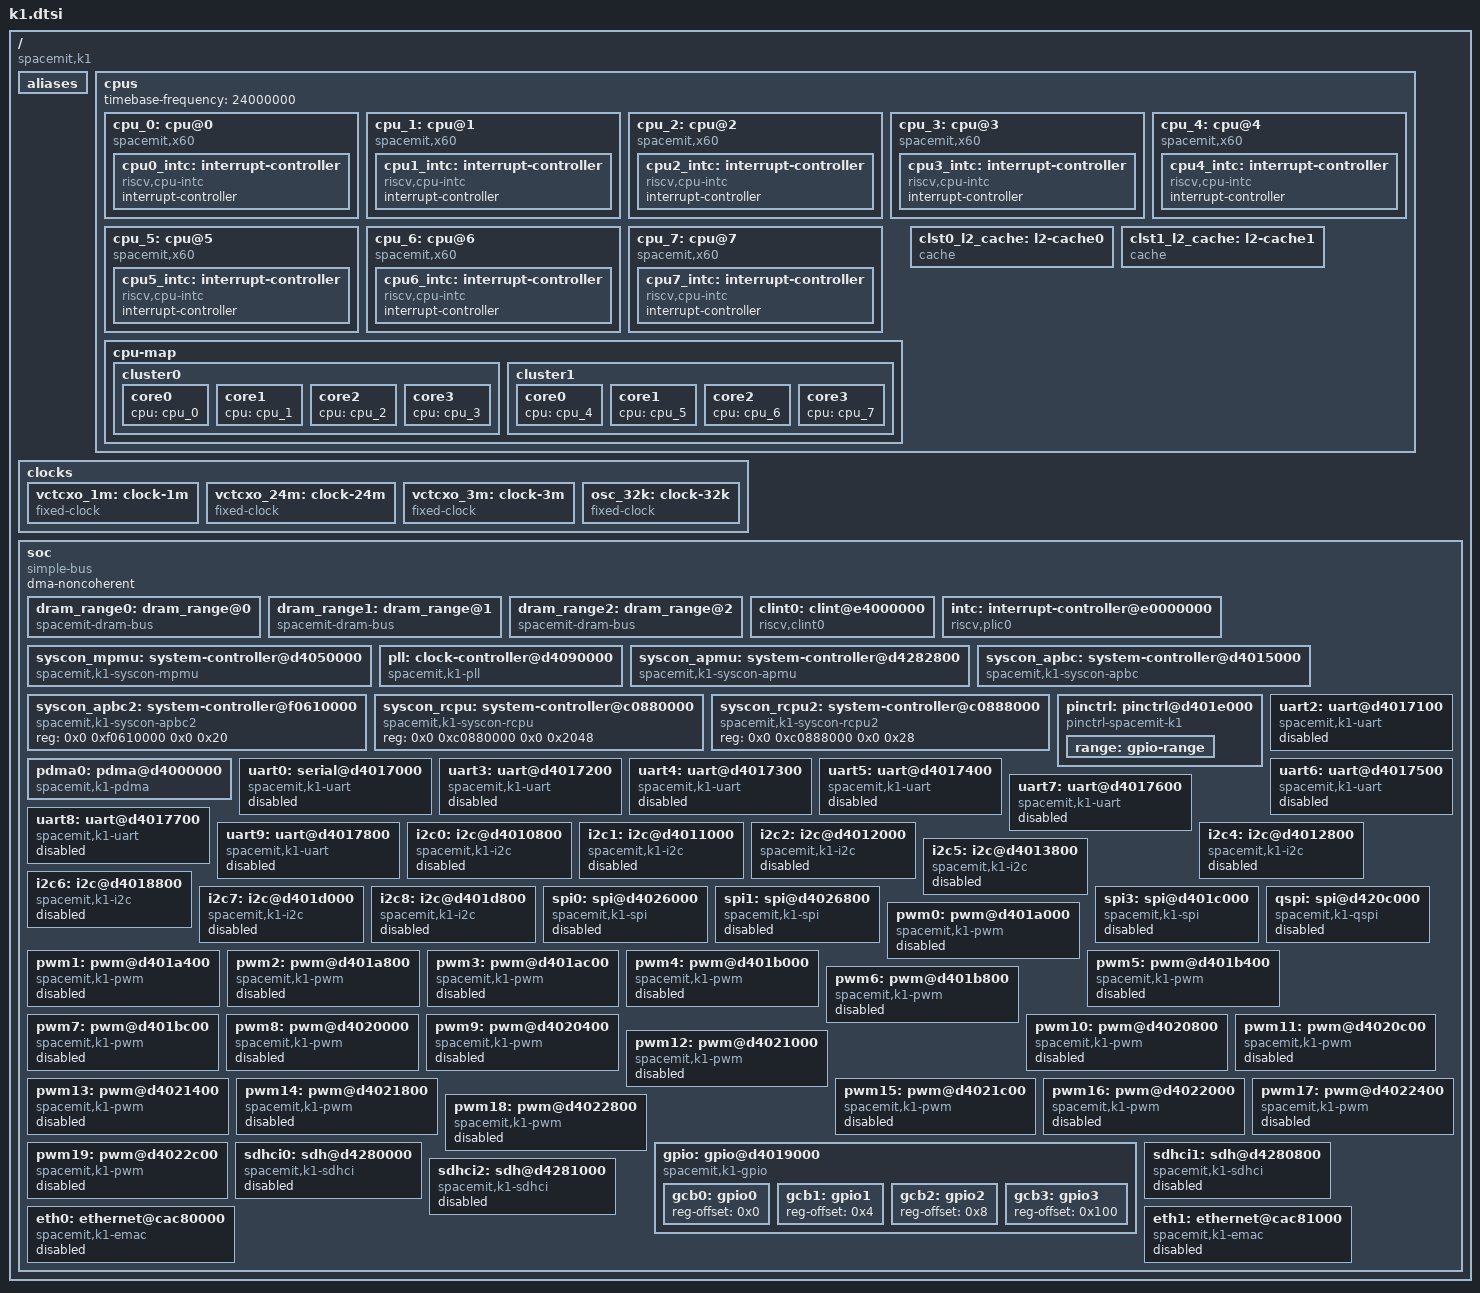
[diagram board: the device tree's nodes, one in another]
// SPDX-License-Identifier: (GPL-2.0 OR MIT)
/* Copyright (c) 2022 Spacemit, Inc */

/dts-v1/;

#include <dt-bindings/clock/spacemit,k1-syscon.h>
#include <dt-bindings/dma/spacemit-k1-dma.h>
#include <dt-bindings/mmc/spacemit-k1-sdhci.h>

/ {
	compatible = "spacemit,k1";
	#address-cells = <2>;
	#size-cells = <2>;

	aliases {
		serial0 = &uart0;
		serial1 = &uart2;
		serial2 = &uart3;
		serial3 = &uart4;
		serial4 = &uart5;
		serial5 = &uart6;
		serial6 = &uart7;
		serial7 = &uart8;
		serial8 = &uart9;
		mmc0 = &sdhci0;
		mmc1 = &sdhci1;
		mmc2 = &sdhci2;
		ethernet0 = &eth0;
		ethernet1 = &eth1;
	};

	cpus: cpus {
		#address-cells = <1>;
		#size-cells = <0>;
		timebase-frequency = <24000000>;
		cpu_0: cpu@0 {
			compatible = "spacemit,x60", "riscv";
			device_type = "cpu";
			model = "Spacemit(R) X60";
			reg = <0>;
			status = "okay";
			riscv,isa = "rv64imafdcv";
			riscv,isa-base = "rv64i";
			riscv,isa-extensions = "i", "m", "a", "f", "d", "c", "v",
					"zicbom", "zicboz", "zicntr", "zicond",
					"zicsr", "zifencei", "zihintpause", "zihpm",
					"zfh", "zfhmin", "zba", "zbb", "zbc", "zbs",
					"zkt", "zvfh", "zvfhmin", "zvkt", "sscofpmf",
					"sstc", "svinval", "svnapot", "svpbmt" ;
			riscv,cbom-block-size = <64>;
			riscv,cboz-block-size = <64>;
			i-cache-block-size = <64>;
			i-cache-size = <32768>;
			i-cache-sets = <128>;
			d-cache-block-size = <64>;
			d-cache-size = <32768>;
			d-cache-sets = <128>;
			next-level-cache = <&clst0_l2_cache>;
			mmu-type = "riscv,sv39";
			cpu-ai = "true";

			cpu0_intc: interrupt-controller {
				#interrupt-cells = <1>;
				compatible = "riscv,cpu-intc";
				interrupt-controller;
			};
		};

		cpu_1: cpu@1 {
			device_type = "cpu";
			reg = <1>;
			status = "okay";
			compatible = "spacemit,x60", "riscv";
			model = "Spacemit(R) X60";
			riscv,isa = "rv64imafdcv";
			riscv,isa-base = "rv64i";
			riscv,isa-extensions = "i", "m", "a", "f", "d", "c", "v",
					"zicbom", "zicboz", "zicntr", "zicond",
					"zicsr", "zifencei", "zihintpause", "zihpm",
					"zfh", "zfhmin", "zba", "zbb", "zbc", "zbs",
					"zkt", "zvfh", "zvfhmin", "zvkt", "sscofpmf",
					"sstc", "svinval", "svnapot", "svpbmt" ;
			riscv,cbom-block-size = <64>;
			riscv,cboz-block-size = <64>;
			i-cache-block-size = <64>;
			i-cache-size = <32768>;
			i-cache-sets = <128>;
			d-cache-block-size = <64>;
			d-cache-size = <32768>;
			d-cache-sets = <128>;
			next-level-cache = <&clst0_l2_cache>;
			mmu-type = "riscv,sv39";
			cpu-ai = "true";

			cpu1_intc: interrupt-controller {
				#interrupt-cells = <1>;
				compatible = "riscv,cpu-intc";
				interrupt-controller;
			};
		};

		cpu_2: cpu@2 {
			device_type = "cpu";
			reg = <2>;
			status = "okay";
			compatible = "spacemit,x60", "riscv";
			model = "Spacemit(R) X60";
			riscv,isa = "rv64imafdcv";
			riscv,isa-base = "rv64i";
			riscv,isa-extensions = "i", "m", "a", "f", "d", "c", "v",
					"zicbom", "zicboz", "zicntr", "zicond",
					"zicsr", "zifencei", "zihintpause", "zihpm",
					"zfh", "zfhmin", "zba", "zbb", "zbc", "zbs",
					"zkt", "zvfh", "zvfhmin", "zvkt", "sscofpmf",
					"sstc", "svinval", "svnapot", "svpbmt" ;
			riscv,cbom-block-size = <64>;
			riscv,cboz-block-size = <64>;
			i-cache-block-size = <64>;
			i-cache-size = <32768>;
			i-cache-sets = <128>;
			d-cache-block-size = <64>;
			d-cache-size = <32768>;
			d-cache-sets = <128>;
			next-level-cache = <&clst0_l2_cache>;
			mmu-type = "riscv,sv39";
			cpu-ai = "true";

			cpu2_intc: interrupt-controller {
				#interrupt-cells = <1>;
				compatible = "riscv,cpu-intc";
				interrupt-controller;
			};
		};

		cpu_3: cpu@3 {
			device_type = "cpu";
			reg = <3>;
			status = "okay";
			compatible = "spacemit,x60", "riscv";
			model = "Spacemit(R) X60";
			riscv,isa = "rv64imafdcv";
			riscv,isa-base = "rv64i";
			riscv,isa-extensions = "i", "m", "a", "f", "d", "c", "v",
					"zicbom", "zicboz", "zicntr", "zicond",
					"zicsr", "zifencei", "zihintpause", "zihpm",
					"zfh", "zfhmin", "zba", "zbb", "zbc", "zbs",
					"zkt", "zvfh", "zvfhmin", "zvkt", "sscofpmf",
					"sstc", "svinval", "svnapot", "svpbmt" ;
			riscv,cbom-block-size = <64>;
			riscv,cboz-block-size = <64>;
			i-cache-block-size = <64>;
			i-cache-size = <32768>;
			i-cache-sets = <128>;
			d-cache-block-size = <64>;
			d-cache-size = <32768>;
			d-cache-sets = <128>;
			next-level-cache = <&clst0_l2_cache>;
			mmu-type = "riscv,sv39";
			cpu-ai = "true";

			cpu3_intc: interrupt-controller {
				#interrupt-cells = <1>;
				compatible = "riscv,cpu-intc";
				interrupt-controller;
			};
		};

		cpu_4: cpu@4 {
			device_type = "cpu";
			reg = <4>;
			status = "okay";
			compatible = "spacemit,x60", "riscv";
			model = "Spacemit(R) X60";
			riscv,isa = "rv64imafdcv";
			riscv,isa-base = "rv64i";
			riscv,isa-extensions = "i", "m", "a", "f", "d", "c", "v",
					"zicbom", "zicboz", "zicntr", "zicond",
					"zicsr", "zifencei", "zihintpause", "zihpm",
					"zfh", "zfhmin", "zba", "zbb", "zbc", "zbs",
					"zkt", "zvfh", "zvfhmin", "zvkt", "sscofpmf",
					"sstc", "svinval", "svnapot", "svpbmt" ;
			riscv,cbom-block-size = <64>;
			riscv,cboz-block-size = <64>;
			i-cache-block-size = <64>;
			i-cache-size = <32768>;
			i-cache-sets = <128>;
			d-cache-block-size = <64>;
			d-cache-size = <32768>;
			d-cache-sets = <128>;
			next-level-cache = <&clst1_l2_cache>;
			mmu-type = "riscv,sv39";

			cpu4_intc: interrupt-controller {
				#interrupt-cells = <1>;
				compatible = "riscv,cpu-intc";
				interrupt-controller;
			};
		};

		cpu_5: cpu@5 {
			device_type = "cpu";
			reg = <5>;
			status = "okay";
			compatible = "spacemit,x60", "riscv";
			model = "Spacemit(R) X60";
			riscv,isa = "rv64imafdcv";
			riscv,isa-base = "rv64i";
			riscv,isa-extensions = "i", "m", "a", "f", "d", "c", "v",
					"zicbom", "zicboz", "zicntr", "zicond",
					"zicsr", "zifencei", "zihintpause", "zihpm",
					"zfh", "zfhmin", "zba", "zbb", "zbc", "zbs",
					"zkt", "zvfh", "zvfhmin", "zvkt", "sscofpmf",
					"sstc", "svinval", "svnapot", "svpbmt" ;
			riscv,cbom-block-size = <64>;
			riscv,cboz-block-size = <64>;
			i-cache-block-size = <64>;
			i-cache-size = <32768>;
			i-cache-sets = <128>;
			d-cache-block-size = <64>;
			d-cache-size = <32768>;
			d-cache-sets = <128>;
			next-level-cache = <&clst1_l2_cache>;
			mmu-type = "riscv,sv39";

			cpu5_intc: interrupt-controller {
				#interrupt-cells = <1>;
				compatible = "riscv,cpu-intc";
				interrupt-controller;
			};
		};

		cpu_6: cpu@6 {
			device_type = "cpu";
			reg = <6>;
			status = "okay";
			compatible = "spacemit,x60", "riscv";
			model = "Spacemit(R) X60";
			riscv,isa = "rv64imafdcv";
			riscv,isa-base = "rv64i";
			riscv,isa-extensions = "i", "m", "a", "f", "d", "c", "v",
					"zicbom", "zicboz", "zicntr", "zicond",
					"zicsr", "zifencei", "zihintpause", "zihpm",
					"zfh", "zfhmin", "zba", "zbb", "zbc", "zbs",
					"zkt", "zvfh", "zvfhmin", "zvkt", "sscofpmf",
					"sstc", "svinval", "svnapot", "svpbmt" ;
			riscv,cbom-block-size = <64>;
			riscv,cboz-block-size = <64>;
			i-cache-block-size = <64>;
			i-cache-size = <32768>;
			i-cache-sets = <128>;
			d-cache-block-size = <64>;
			d-cache-size = <32768>;
			d-cache-sets = <128>;
			next-level-cache = <&clst1_l2_cache>;
			mmu-type = "riscv,sv39";

			cpu6_intc: interrupt-controller {
				#interrupt-cells = <1>;
				compatible = "riscv,cpu-intc";
				interrupt-controller;
			};
		};

		cpu_7: cpu@7 {
			device_type = "cpu";
			reg = <7>;
			status = "okay";
			compatible = "spacemit,x60", "riscv";
			model = "Spacemit(R) X60";
			riscv,isa = "rv64imafdcv";
			riscv,isa-base = "rv64i";
			riscv,isa-extensions = "i", "m", "a", "f", "d", "c", "v",
					"zicbom", "zicboz", "zicntr", "zicond",
					"zicsr", "zifencei", "zihintpause", "zihpm",
					"zfh", "zfhmin", "zba", "zbb", "zbc", "zbs",
					"zkt", "zvfh", "zvfhmin", "zvkt", "sscofpmf",
					"sstc", "svinval", "svnapot", "svpbmt" ;
			riscv,cbom-block-size = <64>;
			riscv,cboz-block-size = <64>;
			i-cache-block-size = <64>;
			i-cache-size = <32768>;
			i-cache-sets = <128>;
			d-cache-block-size = <64>;
			d-cache-size = <32768>;
			d-cache-sets = <128>;
			next-level-cache = <&clst1_l2_cache>;
			mmu-type = "riscv,sv39";

			cpu7_intc: interrupt-controller {
				#interrupt-cells = <1>;
				compatible = "riscv,cpu-intc";
				interrupt-controller;
			};
		};

		cpu-map {
			cluster0 {
				core0 {
					cpu = <&cpu_0>;
				};

				core1 {
					cpu = <&cpu_1>;
				};

				core2 {
					cpu = <&cpu_2>;
				};

				core3 {
					cpu = <&cpu_3>;
				};
			};

			cluster1 {
				core0 {
					cpu = <&cpu_4>;
				};

				core1 {
					cpu = <&cpu_5>;
				};

				core2 {
					cpu = <&cpu_6>;
				};

				core3 {
					cpu = <&cpu_7>;
				};
			};
		};

		clst0_l2_cache: l2-cache0 {
			compatible = "cache";
			cache-block-size = <64>;
			cache-level = <2>;
			cache-size = <524288>;
			cache-sets = <512>;
			cache-unified;
		};

		clst1_l2_cache: l2-cache1 {
			compatible = "cache";
			cache-block-size = <64>;
			cache-level = <2>;
			cache-size = <524288>;
			cache-sets = <512>;
			cache-unified;
		};
	};

	clocks {
		vctcxo_1m: clock-1m {
			compatible = "fixed-clock";
			clock-frequency = <1000000>;
			clock-output-names = "vctcxo_1m";
			#clock-cells = <0>;
		};

		vctcxo_24m: clock-24m {
			compatible = "fixed-clock";
			clock-frequency = <24000000>;
			clock-output-names = "vctcxo_24m";
			#clock-cells = <0>;
		};

		vctcxo_3m: clock-3m {
			compatible = "fixed-clock";
			clock-frequency = <3000000>;
			clock-output-names = "vctcxo_3m";
			#clock-cells = <0>;
		};

		osc_32k: clock-32k {
			compatible = "fixed-clock";
			clock-frequency = <32000>;
			clock-output-names = "osc_32k";
			#clock-cells = <0>;
		};
	};

	soc: soc {
		compatible = "simple-bus";
		#address-cells = <2>;
		#size-cells = <2>;
		dma-noncoherent;
		ranges;

		/*
		 * dram mapping for dma/usb/sdh for ex,
		 * only 2GB available for devices.
		 */
		dram_range0: dram_range@0 {
			compatible = "spacemit-dram-bus";
			#address-cells = <2>;
			#size-cells = <2>;
			dma-ranges = <0x0 0x00000000 0x0 0x00000000 0x0 0x80000000>;
			#interconnect-cells = <0>;
			status = "okay";
		};

		/*
		 * dram mapping for vpu/gpu/dpu/v2d/isp/csi/vi/cpp,
		 * and eth/crypto/jpu for ex.
		 * 4GB space is available for devices, and the mapping is:
		 * 0~2GB of device's address space is mapping to 0~2GB of cpu's
		 * 2~4GB of device's address space is mapping to 4~6GB of cpu's
		 */
		dram_range1: dram_range@1 {
			compatible = "spacemit-dram-bus";
			#address-cells = <2>;
			#size-cells = <2>;
			dma-ranges = <0x0 0x00000000 0x0 0x00000000 0x0 0x80000000>,
				     <0x0 0x80000000 0x1 0x00000000 0x0 0x80000000>;
			#interconnect-cells = <0>;
			status = "okay";
		};

		/*
		 * dram mapping for pcie0/pcie1/pcie2 for ex.
		 * 14GB space is available for devices, and the mapping is:
		 * 0~2GB of device's address space is mapping to 0~2GB of cpu's
		 * 4~16GB of device's address space is mapping to 6~16GB of cpu's
		 * the 2~4GB of devcie's address space is io area
		 */
		dram_range2: dram_range@2 {
			compatible = "spacemit-dram-bus";
			#address-cells = <2>;
			#size-cells = <2>;
			dma-ranges = <0x0 0x00000000 0x0 0x00000000 0x0 0x80000000>,
				     <0x1 0x00000000 0x1 0x80000000 0x3 0x00000000>;
			#interconnect-cells = <0>;
			status = "okay";
		};

		clint0: clint@e4000000 {
			compatible = "riscv,clint0";
			interrupts-extended = <
				&cpu0_intc  3 &cpu0_intc  7
				&cpu1_intc  3 &cpu1_intc  7
				&cpu2_intc  3 &cpu2_intc  7
				&cpu3_intc  3 &cpu3_intc  7
				&cpu4_intc  3 &cpu4_intc  7
				&cpu5_intc  3 &cpu5_intc  7
				&cpu6_intc  3 &cpu6_intc  7
				&cpu7_intc  3 &cpu7_intc  7
			>;
			reg = <0x0 0xE4000000 0x0 0x00010000>;
		};

		intc: interrupt-controller@e0000000 {
			#interrupt-cells = <1>;
			compatible = "riscv,plic0";
			interrupt-controller;
			interrupts-extended = <
				&cpu0_intc 11 &cpu0_intc 9
				&cpu1_intc 11 &cpu1_intc 9
				&cpu2_intc 11 &cpu2_intc 9
				&cpu3_intc 11 &cpu3_intc 9
				&cpu4_intc 11 &cpu4_intc 9
				&cpu5_intc 11 &cpu5_intc 9
				&cpu6_intc 11 &cpu6_intc 9
				&cpu7_intc 11 &cpu7_intc 9
			>;
			reg = <0x0 0xE0000000 0x0 0x04000000>;
			reg-names = "control";
			riscv,max-priority = <7>;
			riscv,ndev = <159>;
		};

		syscon_mpmu: system-controller@d4050000 {
			compatible = "spacemit,k1-syscon-mpmu";
			reg = <0x0 0xd4050000 0x0 0x209c>;
			clocks = <&osc_32k>, <&vctcxo_1m>, <&vctcxo_3m>,
				 <&vctcxo_24m>;
			clock-names = "osc", "vctcxo_1m", "vctcxo_3m",
				      "vctcxo_24m";
			#clock-cells = <1>;
			#power-domain-cells = <1>;
			#reset-cells = <1>;
		};

		pll: clock-controller@d4090000 {
			compatible = "spacemit,k1-pll";
			reg = <0x0 0xd4090000 0x0 0x1000>;
			clocks = <&vctcxo_24m>;
			spacemit,mpmu = <&syscon_mpmu>;
			#clock-cells = <1>;
		};

		syscon_apmu: system-controller@d4282800 {
			compatible = "spacemit,k1-syscon-apmu";
			reg = <0x0 0xd4282800 0x0 0x400>;
			clocks = <&osc_32k>, <&vctcxo_1m>, <&vctcxo_3m>,
				 <&vctcxo_24m>;
			clock-names = "osc", "vctcxo_1m", "vctcxo_3m",
				      "vctcxo_24m";
			#clock-cells = <1>;
			#power-domain-cells = <1>;
			#reset-cells = <1>;
		};

		syscon_apbc: system-controller@d4015000 {
			compatible = "spacemit,k1-syscon-apbc";
			reg = <0x0 0xd4015000 0x0 0x1000>;
			clocks = <&osc_32k>, <&vctcxo_1m>, <&vctcxo_3m>,
				 <&vctcxo_24m>;
			clock-names = "osc", "vctcxo_1m", "vctcxo_3m",
				      "vctcxo_24m";
			#clock-cells = <1>;
			#reset-cells = <1>;
		};

		syscon_apbc2: system-controller@f0610000 {
			compatible = "spacemit,k1-syscon-apbc2";
			reg = <0x0 0xf0610000 0x0 0x20>;
			#reset-cells = <1>;
		};

		syscon_rcpu: system-controller@c0880000 {
			compatible = "spacemit,k1-syscon-rcpu";
			reg = <0x0 0xc0880000 0x0 0x2048>;
			#reset-cells = <1>;
		};

		syscon_rcpu2: system-controller@c0888000 {
			compatible = "spacemit,k1-syscon-rcpu2";
			reg = <0x0 0xc0888000 0x0 0x28>;
			#reset-cells = <1>;
		};

		pinctrl: pinctrl@d401e000 {
			compatible = "pinctrl-spacemit-k1";
			reg = <0x0 0xd401e000 0x0 0x250>,
			      <0x0 0xd4019800 0x0 0x10>,
			      <0x0 0xd4019000 0x0 0x800>;
			#address-cells = <1>;
			#size-cells = <1>;
			#pinctrl-cells = <2>;
			#gpio-range-cells = <3>;

			pinctrl-single,register-width = <32>;
			pinctrl-single,function-mask = <0xff77>;

			clocks = <&syscon_apbc CLK_AIB>,
				 <&syscon_apbc CLK_AIB_BUS>;
			clock-names = "func", "bus";
			resets = <&syscon_apbc RESET_AIB>;
			reset-names = "aib_rst";

			interrupt-parent = <&intc>;
			interrupts = <60>;
			interrupt-controller;
			#interrupt-cells = <1>;

			range: gpio-range {
				#pinctrl-single,gpio-range-cells = <3>;
			};
		};

		pdma0: pdma@d4000000 {
			compatible = "spacemit,k1-pdma";
			reg = <0x0 0xd4000000 0x0 0x4000>;
			interrupts = <72>;
			interrupt-parent = <&intc>;
			clocks = <&syscon_apmu CLK_DMA>;
			resets = <&syscon_apmu RESET_DMA>;
			#dma-cells= <2>;
			#dma-channels = <16>;
			max-burst-size = <64>;
			reserved-channels = <15 45>;
			interconnects = <&dram_range0>;
			interconnect-names = "dma-mem";
			status = "ok";
		};

		uart0: serial@d4017000 {
			compatible = "spacemit,k1-uart", "intel,xscale-uart";
			reg = <0x0 0xd4017000 0x0 0x100>;
			interrupt-parent = <&intc>;
			interrupts = <42>;
			clocks = <&syscon_apbc CLK_UART0>,
				 <&syscon_apbc CLK_UART0_BUS>;
			clock-names = "core", "bus";
			resets = <&syscon_apbc RESET_UART0>;
			reg-shift = <2>;
			reg-io-width = <4>;
			status = "disabled";
		};

		uart2: uart@d4017100 {
			compatible = "spacemit,k1-uart", "intel,xscale-uart";
			reg = <0x0 0xd4017100 0x0 0x100>;
			interrupt-parent = <&intc>;
			interrupts = <44>;
			clocks = <&syscon_apbc CLK_UART2>,
				 <&syscon_apbc CLK_UART2_BUS>;
			clock-names = "core", "bus";
			resets = <&syscon_apbc RESET_UART2>;
			status = "disabled";
		};

		uart3: uart@d4017200 {
			compatible = "spacemit,k1-uart", "intel,xscale-uart";
			reg = <0x0 0xd4017200 0x0 0x100>;
			interrupt-parent = <&intc>;
			interrupts = <45>;
			clocks = <&syscon_apbc CLK_UART3>,
				 <&syscon_apbc CLK_UART3_BUS>;
			clock-names = "core", "bus";
			resets = <&syscon_apbc RESET_UART3>;
			status = "disabled";
		};

		uart4: uart@d4017300 {
			compatible = "spacemit,k1-uart", "intel,xscale-uart";
			interrupt-parent = <&intc>;
			reg = <0x0 0xd4017300 0x0 0x100>;
			interrupts = <46>;
			clocks = <&syscon_apbc CLK_UART4>,
				 <&syscon_apbc CLK_UART4_BUS>;
			clock-names = "core", "bus";
				resets = <&syscon_apbc RESET_UART4>;
			status = "disabled";
		};

		uart5: uart@d4017400 {
			compatible = "spacemit,k1-uart", "intel,xscale-uart";
			interrupt-parent = <&intc>;
			reg = <0x0 0xd4017400 0x0 0x100>;
			interrupts = <47>;
			clocks = <&syscon_apbc CLK_UART5>,
				 <&syscon_apbc CLK_UART5_BUS>;
			clock-names = "core", "bus";
			resets = <&syscon_apbc RESET_UART5>;
			status = "disabled";
		};

		uart6: uart@d4017500 {
			compatible = "spacemit,k1-uart", "intel,xscale-uart";
			interrupt-parent = <&intc>;
			reg = <0x0 0xd4017500 0x0 0x100>;
			interrupts = <48>;
			clocks = <&syscon_apbc CLK_UART6>,
				 <&syscon_apbc CLK_UART6_BUS>;
			clock-names = "core", "bus";
			resets = <&syscon_apbc RESET_UART6>;
			status = "disabled";
		};

		uart7: uart@d4017600 {
			compatible = "spacemit,k1-uart", "intel,xscale-uart";
			interrupt-parent = <&intc>;
			reg = <0x0 0xd4017600 0x0 0x100>;
			interrupts = <49>;
			clocks = <&syscon_apbc CLK_UART7>,
				 <&syscon_apbc CLK_UART7_BUS>;
			clock-names = "core", "bus";
			resets = <&syscon_apbc RESET_UART7>;
			status = "disabled";
		};

		uart8: uart@d4017700 {
			compatible = "spacemit,k1-uart", "intel,xscale-uart";
			interrupt-parent = <&intc>;
			reg = <0x0 0xd4017700 0x0 0x100>;
			interrupts = <50>;
			clocks = <&syscon_apbc CLK_UART8>,
				 <&syscon_apbc CLK_UART8_BUS>;
			clock-names = "core", "bus";
			resets = <&syscon_apbc RESET_UART8>;
			status = "disabled";
		};

		uart9: uart@d4017800 {
			compatible = "spacemit,k1-uart", "intel,xscale-uart";
			interrupt-parent = <&intc>;
			reg = <0x0 0xd4017800 0x0 0x100>;
			interrupts = <51>;
			clocks = <&syscon_apbc CLK_UART9>,
				 <&syscon_apbc CLK_UART9_BUS>;
			clock-names = "core", "bus";
			resets = <&syscon_apbc RESET_UART9>;
			status = "disabled";
		};

		i2c0: i2c@d4010800 {
			compatible = "spacemit,k1-i2c";
			spacemit,adapter-id = <0>;
			reg = <0x0 0xd4010800 0x0 0x38>;
			#address-cells = <1>;
			#size-cells = <0>;
			interrupt-parent = <&intc>;
			interrupts = <36>;
			clocks = <&syscon_apbc CLK_TWSI0>,
				 <&syscon_apbc CLK_TWSI0_BUS>;
			clock-names = "func", "bus";
			resets = <&syscon_apbc RESET_TWSI0>;
			spacemit,i2c-master-code = /bits/ 8 <0x0e>;
			spacemit,i2c-clk-rate = <32000000>;
			spacemit,i2c-lcr = <0x82c469f>;
			spacemit,i2c-wcr = <0x142a>;
			/* apb clock: 26MHz or 52MHz */
			spacemit,apb_clock = <52000000>;
			status = "disabled";
		};

		i2c1: i2c@d4011000 {
			compatible = "spacemit,k1-i2c";
			spacemit,adapter-id = <1>;
			reg = <0x0 0xd4011000 0x0 0x38>;
			#address-cells = <1>;
			#size-cells = <0>;
			interrupt-parent = <&intc>;
			interrupts = <37>;
			clocks = <&syscon_apbc CLK_TWSI1>,
				 <&syscon_apbc CLK_TWSI1_BUS>;
			clock-names = "func", "bus";
			resets = <&syscon_apbc RESET_TWSI1>;
			spacemit,i2c-master-code = /bits/ 8 <0x0e>;
			spacemit,i2c-clk-rate = <32000000>;
			spacemit,i2c-lcr = <0x82c469f>;
			spacemit,i2c-wcr = <0x142a>;
			/* apb clock: 26MHz or 52MHz */
			spacemit,apb_clock = <52000000>;
			status = "disabled";
		};

		i2c2: i2c@d4012000 {
			compatible = "spacemit,k1-i2c";
			spacemit,adapter-id = <2>;
			reg = <0x0 0xd4012000 0x0 0x38>;
			#address-cells = <1>;
			#size-cells = <0>;
			interrupt-parent = <&intc>;
			interrupts = <38>;
			clocks = <&syscon_apbc CLK_TWSI2>,
				 <&syscon_apbc CLK_TWSI2_BUS>;
			clock-names = "func", "bus";
			resets = <&syscon_apbc RESET_TWSI2>;
			spacemit,i2c-master-code = /bits/ 8 <0x0e>;
			spacemit,i2c-clk-rate = <32000000>;
			spacemit,i2c-lcr = <0x82c469f>;
			spacemit,i2c-wcr = <0x142a>;
			/* apb clock: 26MHz or 52MHz */
			spacemit,apb_clock = <52000000>;
			status = "disabled";
		};

		i2c4: i2c@d4012800 {
			compatible = "spacemit,k1-i2c";
			spacemit,adapter-id = <4>;
			reg = <0x0 0xd4012800 0x0 0x38>;
			#address-cells = <1>;
			#size-cells = <0>;
			interrupt-parent = <&intc>;
			interrupts = <40>;
			clocks = <&syscon_apbc CLK_TWSI4>,
				 <&syscon_apbc CLK_TWSI4_BUS>;
			clock-names = "func", "bus";
			resets = <&syscon_apbc RESET_TWSI4>;
			spacemit,i2c-master-code = /bits/ 8 <0x0e>;
			spacemit,i2c-clk-rate = <32000000>;
			spacemit,i2c-lcr = <0x82c469f>;
			spacemit,i2c-wcr = <0x142a>;
			/* apb clock: 26MHz or 52MHz */
			spacemit,apb_clock = <52000000>;
			status = "disabled";
		};

		i2c5: i2c@d4013800 {
			compatible = "spacemit,k1-i2c";
			spacemit,adapter-id = <5>;
			reg = <0x0 0xd4013800 0x0 0x38>;
			#address-cells = <1>;
			#size-cells = <0>;
			interrupt-parent = <&intc>;
			interrupts = <41>;
			clocks = <&syscon_apbc CLK_TWSI5>,
				 <&syscon_apbc CLK_TWSI5_BUS>;
			clock-names = "func", "bus";
			resets = <&syscon_apbc RESET_TWSI5>;
			spacemit,i2c-master-code = /bits/ 8 <0x0e>;
			spacemit,i2c-clk-rate = <32000000>;
			spacemit,i2c-lcr = <0x82c469f>;
			spacemit,i2c-wcr = <0x142a>;
			/* apb clock: 26MHz or 52MHz */
			spacemit,apb_clock = <52000000>;
			status = "disabled";
		};

		i2c6: i2c@d4018800 {
			compatible = "spacemit,k1-i2c";
			spacemit,adapter-id = <6>;
			reg = <0x0 0xd4018800 0x0 0x38>;
			#address-cells = <1>;
			#size-cells = <0>;
			interrupt-parent = <&intc>;
			interrupts = <70>;
			clocks = <&syscon_apbc CLK_TWSI6>,
				 <&syscon_apbc CLK_TWSI6_BUS>;
			clock-names = "func", "bus";
			resets = <&syscon_apbc RESET_TWSI6>;
			spacemit,i2c-master-code = /bits/ 8 <0x0e>;
			spacemit,i2c-clk-rate = <32000000>;
			spacemit,i2c-lcr = <0x82c469f>;
			spacemit,i2c-wcr = <0x142a>;
			/* apb clock: 26MHz or 52MHz */
			spacemit,apb_clock = <52000000>;
			status = "disabled";
		};

		i2c7: i2c@d401d000 {
			compatible = "spacemit,k1-i2c";
			spacemit,adapter-id = <7>;
			reg = <0x0 0xd401d000 0x0 0x38>;
			#address-cells = <1>;
			#size-cells = <0>;
			interrupt-parent = <&intc>;
			interrupts = <18>;
			clocks = <&syscon_apbc CLK_TWSI7>,
				 <&syscon_apbc CLK_TWSI7_BUS>;
			clock-names = "func", "bus";
			resets = <&syscon_apbc RESET_TWSI7>;
			spacemit,i2c-master-code = /bits/ 8 <0x0e>;
			spacemit,i2c-clk-rate = <32000000>;
			spacemit,i2c-lcr = <0x82c469f>;
			spacemit,i2c-wcr = <0x142a>;
			/* apb clock: 26MHz or 52MHz */
			spacemit,apb_clock = <52000000>;
			status = "disabled";
		};

		i2c8: i2c@d401d800 {
			compatible = "spacemit,k1-i2c";
			spacemit,adapter-id = <8>;
			reg = <0x0 0xd401d800 0x0 0x38>;
			#address-cells = <1>;
			#size-cells = <0>;
			interrupt-parent = <&intc>;
			interrupts = <19>;
			clocks = <&syscon_apbc CLK_TWSI8>,
				 <&syscon_apbc CLK_TWSI8_BUS>;
			clock-names = "func", "bus";
			resets = <&syscon_apbc RESET_TWSI8>;
			spacemit,i2c-master-code = /bits/ 8 <0x0e>;
			spacemit,i2c-clk-rate = <32000000>;
			spacemit,i2c-lcr = <0x82c469f>;
			spacemit,i2c-wcr = <0x142a>;
			/* apb clock: 26MHz or 52MHz */
			spacemit,apb_clock = <52000000>;
			status = "disabled";
		};

		spi0: spi@d4026000 {
			compatible = "spacemit,k1-spi";
			reg = <0x0 0xd4026000 0x0 0x30>;
			k1,spi-id = <0>;
			k1,spi-clock-rate = <26000000>;
			dmas = <&pdma0 DMA_SSPA0_RX 1
				&pdma0 DMA_SSPA0_TX 1>;
			dma-names = "rx", "tx";
			interrupt-parent = <&intc>;
			interrupts = <56>;
			clocks = <&syscon_apbc CLK_SSPA0>;
			resets = <&syscon_apbc RESET_SSPA0>;
			#address-cells = <1>;
			#size-cells = <0>;
			interconnects = <&dram_range0>;
			interconnect-names = "dma-mem";
			status = "disabled";
		};

		spi1: spi@d4026800 {
			compatible = "spacemit,k1-spi";
			reg = <0x0 0xd4026800 0x0 0x30>;
			k1,spi-id = <1>;
			k1,spi-clock-rate = <26000000>;
			dmas = <&pdma0 DMA_SSPA1_RX 1
				&pdma0 DMA_SSPA1_TX 1>;
			dma-names = "rx", "tx";
			interrupt-parent = <&intc>;
			interrupts = <57>;
			clocks = <&syscon_apbc CLK_SSPA1>;
			resets = <&syscon_apbc RESET_SSPA1>;
			#address-cells = <1>;
			#size-cells = <0>;
			interconnects = <&dram_range0>;
			interconnect-names = "dma-mem";
			status = "disabled";
		};

		spi3: spi@d401c000 {
			compatible = "spacemit,k1-spi";
			reg = <0x0 0xd401c000 0x0 0x30>;
			k1,spi-id = <3>;
			k1,spi-clock-rate = <26000000>;
			dmas = <&pdma0 DMA_SSP3_RX 1
				&pdma0 DMA_SSP3_TX 1>;
			dma-names = "rx", "tx";
			interrupt-parent = <&intc>;
			interrupts = <55>;
			clocks = <&syscon_apbc CLK_SSP3>;
			resets = <&syscon_apbc RESET_SSP3>;
			#address-cells = <1>;
			#size-cells = <0>;
			interconnects = <&dram_range0>;
			interconnect-names = "dma-mem";
			status = "disabled";
		};

		qspi: spi@d420c000 {
			compatible = "spacemit,k1-qspi";
			#address-cells = <1>;
			#size-cells = <0>;
			reg = <0x0 0xd420c000 0x0 0x1000>,
			      <0x0 0xb8000000 0x0 0xc00000>;
			reg-names = "qspi-base", "qspi-mmap";
			k1,qspi-sfa1ad = <0x4000000>;
			k1,qspi-sfa2ad = <0x100000>;
			k1,qspi-sfb1ad = <0x100000>;
			k1,qspi-sfb2ad = <0x100000>;
			clocks = <&syscon_apmu CLK_QSPI_BUS>,
				 <&syscon_apmu CLK_QSPI>;
			clock-names = "qspi_bus_clk", "qspi_clk";
			resets = <&syscon_apmu RESET_QSPI>,
				 <&syscon_apmu RESET_QSPI_BUS>;
			reset-names = "qspi_reset", "qspi_bus_reset";
			k1,qspi-pmuap-reg = <0xd4282860>;
			k1,qspi-mpmu-acgr-reg = <0xd4051024>;
			k1,qspi-freq = <26500000>;
			k1,qspi-id = <4>;
			interrupts = <117>;
			interrupt-parent = <&intc>;
			k1,qspi-tx-dma = <1>;
			k1,qspi-rx-dma = <1>;
			dmas = <&pdma0 DMA_QSPI_TX 1>;
			dma-names = "tx-dma";
			interconnects = <&dram_range0>;
			interconnect-names = "dma-mem";
			status = "disabled";
		};

		pwm0: pwm@d401a000 {
			compatible = "spacemit,k1-pwm";
			reg = <0x0 0xd401a000 0x0 0x10>;
			#pwm-cells = <1>;
			clocks = <&syscon_apbc CLK_PWM0>;
			resets = <&syscon_apbc RESET_PWM0>;
			status = "disabled";
		};

		pwm1: pwm@d401a400 {
			compatible = "spacemit,k1-pwm";
			reg = <0x0 0xd401a400 0x0 0x10>;
			#pwm-cells = <1>;
			clocks = <&syscon_apbc CLK_PWM1>;
			resets = <&syscon_apbc RESET_PWM1>;
			status = "disabled";
		};

		pwm2: pwm@d401a800 {
			compatible = "spacemit,k1-pwm";
			reg = <0x0 0xd401a800 0x0 0x10>;
			#pwm-cells = <1>;
			clocks = <&syscon_apbc CLK_PWM2>;
			resets = <&syscon_apbc RESET_PWM2>;
			status = "disabled";
		};

		pwm3: pwm@d401ac00 {
			compatible = "spacemit,k1-pwm";
			reg = <0x0 0xd401ac00 0x0 0x10>;
			#pwm-cells = <1>;
			clocks = <&syscon_apbc CLK_PWM3>;
			resets = <&syscon_apbc RESET_PWM3>;
			status = "disabled";
		};

		pwm4: pwm@d401b000 {
			compatible = "spacemit,k1-pwm";
			reg = <0x0 0xd401b000 0x0 0x10>;
			#pwm-cells = <1>;
			clocks = <&syscon_apbc CLK_PWM4>;
			resets = <&syscon_apbc RESET_PWM4>;
			status = "disabled";
		};

		pwm5: pwm@d401b400 {
			compatible = "spacemit,k1-pwm";
			reg = <0x0 0xd401b400 0x0 0x10>;
			#pwm-cells = <1>;
			clocks = <&syscon_apbc CLK_PWM5>;
			resets = <&syscon_apbc RESET_PWM5>;
			status = "disabled";
		};

		pwm6: pwm@d401b800 {
			compatible = "spacemit,k1-pwm";
			reg = <0x0 0xd401b800 0x0 0x10>;
			#pwm-cells = <1>;
			clocks = <&syscon_apbc CLK_PWM6>;
			resets = <&syscon_apbc RESET_PWM6>;
			status = "disabled";
		};

		pwm7: pwm@d401bc00 {
			compatible = "spacemit,k1-pwm";
			reg = <0x0 0xd401bc00 0x0 0x10>;
			#pwm-cells = <1>;
			clocks = <&syscon_apbc CLK_PWM7>;
			resets = <&syscon_apbc RESET_PWM7>;
			status = "disabled";
		};

		pwm8: pwm@d4020000 {
			compatible = "spacemit,k1-pwm";
			reg = <0x0 0xd4020000 0x0 0x10>;
			#pwm-cells = <1>;
			clocks = <&syscon_apbc CLK_PWM8>;
			resets = <&syscon_apbc RESET_PWM8>;
			status = "disabled";
		};

		pwm9: pwm@d4020400 {
			compatible = "spacemit,k1-pwm";
			reg = <0x0 0xd4020400 0x0 0x10>;
			#pwm-cells = <1>;
			clocks = <&syscon_apbc CLK_PWM9>;
			resets = <&syscon_apbc RESET_PWM9>;
			status = "disabled";
		};

		pwm10: pwm@d4020800 {
			compatible = "spacemit,k1-pwm";
			reg = <0x0 0xd4020800 0x0 0x10>;
			#pwm-cells = <1>;
			clocks = <&syscon_apbc CLK_PWM10>;
			resets = <&syscon_apbc RESET_PWM10>;
			status = "disabled";
		};

		pwm11: pwm@d4020c00 {
			compatible = "spacemit,k1-pwm";
			reg = <0x0 0xd4020c00 0x0 0x10>;
			#pwm-cells = <1>;
			clocks = <&syscon_apbc CLK_PWM11>;
			resets = <&syscon_apbc RESET_PWM11>;
			status = "disabled";
		};

		pwm12: pwm@d4021000 {
			compatible = "spacemit,k1-pwm";
			reg = <0x0 0xd4021000 0x0 0x10>;
			#pwm-cells = <1>;
			clocks = <&syscon_apbc CLK_PWM12>;
			resets = <&syscon_apbc RESET_PWM12>;
			status = "disabled";
		};

		pwm13: pwm@d4021400 {
			compatible = "spacemit,k1-pwm";
			reg = <0x0 0xd4021400 0x0 0x10>;
			#pwm-cells = <1>;
			clocks = <&syscon_apbc CLK_PWM13>;
			resets = <&syscon_apbc RESET_PWM13>;
			status = "disabled";
		};

		pwm14: pwm@d4021800 {
			compatible = "spacemit,k1-pwm";
			reg = <0x0 0xd4021800 0x0 0x10>;
			#pwm-cells = <1>;
			clocks = <&syscon_apbc CLK_PWM14>;
			resets = <&syscon_apbc RESET_PWM14>;
			status = "disabled";
		};

		pwm15: pwm@d4021c00 {
			compatible = "spacemit,k1-pwm";
			reg = <0x0 0xd4021c00 0x0 0x10>;
			#pwm-cells = <1>;
			clocks = <&syscon_apbc CLK_PWM15>;
			resets = <&syscon_apbc RESET_PWM15>;
			status = "disabled";
		};

		pwm16: pwm@d4022000 {
			compatible = "spacemit,k1-pwm";
			reg = <0x0 0xd4022000 0x0 0x10>;
			#pwm-cells = <1>;
			clocks = <&syscon_apbc CLK_PWM16>;
			resets = <&syscon_apbc RESET_PWM16>;
			status = "disabled";
		};

		pwm17: pwm@d4022400 {
			compatible = "spacemit,k1-pwm";
			reg = <0x0 0xd4022400 0x0 0x10>;
			#pwm-cells = <1>;
			clocks = <&syscon_apbc CLK_PWM17>;
			resets = <&syscon_apbc RESET_PWM17>;
			status = "disabled";
		};

		pwm18: pwm@d4022800 {
			compatible = "spacemit,k1-pwm";
			reg = <0x0 0xd4022800 0x0 0x10>;
			#pwm-cells = <1>;
			clocks = <&syscon_apbc CLK_PWM18>;
			resets = <&syscon_apbc RESET_PWM18>;
			status = "disabled";
		};

		pwm19: pwm@d4022c00 {
			compatible = "spacemit,k1-pwm";
			reg = <0x0 0xd4022c00 0x0 0x10>;
			#pwm-cells = <1>;
			clocks = <&syscon_apbc CLK_PWM19>;
			resets = <&syscon_apbc RESET_PWM19>;
			status = "disabled";
		};

		gpio: gpio@d4019000 {
			compatible = "spacemit,k1-gpio";
			reg = <0x0 0xd4019000 0x0 0x800>;
			gpio-controller;
			#gpio-cells = <2>;
			interrupts = <58>;
			clocks = <&syscon_apbc CLK_GPIO>,
				 <&syscon_apbc CLK_GPIO_BUS>;
			clock-names = "core", "bus";
			interrupt-names = "gpio_mux";
			interrupt-parent = <&intc>;
			interrupt-controller;
			#interrupt-cells = <2>;

			gcb0: gpio0 {
				reg-offset = <0x0>;
			};

			gcb1: gpio1 {
				reg-offset = <0x4>;
			};

			gcb2: gpio2 {
				reg-offset = <0x8>;
			};

			gcb3: gpio3 {
				reg-offset = <0x100>;
			};
		};

		sdhci0: sdh@d4280000 {
			compatible = "spacemit,k1-sdhci";
			reg = <0x0 0xd4280000 0x0 0x200>;
			interrupts = <99>;
			interrupt-parent = <&intc>;
			clocks = <&syscon_apmu CLK_SDH_AXI>,
				 <&syscon_apmu CLK_SDH0>,
				 <&syscon_apbc CLK_AIB_BUS>,
				 <&syscon_apmu CLK_AIB>;
			clock-names = "core", "io", "aib-bus", "aib";
			resets = <&syscon_apmu RESET_SDH_AXI>,
				 <&syscon_apmu RESET_SDH0>;
			reset-names = "core", "io";
			interconnects = <&dram_range0>;
			interconnect-names = "dma-mem";
			status = "disabled";
		};

		sdhci1: sdh@d4280800 {
			compatible = "spacemit,k1-sdhci";
			reg = <0x0 0xd4280800 0x0 0x200>;
			interrupts = <100>;
			interrupt-parent = <&intc>;
			clocks = <&syscon_apmu CLK_SDH_AXI>,
				 <&syscon_apmu CLK_SDH1>;
			clock-names = "core", "io";
			resets = <&syscon_apmu RESET_SDH_AXI>,
				 <&syscon_apmu RESET_SDH1>;
			reset-names = "core", "io";
			interconnects = <&dram_range0>;
			interconnect-names = "dma-mem";
			status = "disabled";
		};

		sdhci2: sdh@d4281000 {
			compatible = "spacemit,k1-sdhci";
			reg = <0x0 0xd4281000 0x0 0x200>;
			interrupts = <101>;
			interrupt-parent = <&intc>;
			clocks = <&syscon_apmu CLK_SDH_AXI>,
				 <&syscon_apmu CLK_SDH2>;
			clock-names = "core", "io";
			resets = <&syscon_apmu RESET_SDH_AXI>,
				 <&syscon_apmu RESET_SDH2>;
			reset-names = "core", "io";
			interconnects = <&dram_range0>;
			interconnect-names = "dma-mem";
			status = "disabled";
		};

		eth0: ethernet@cac80000 {
			compatible = "spacemit,k1-emac";
			reg = <0x0 0xCAC80000 0x0 0x420>;
			k1,apmu-base-reg = <0xD4282800>;
			ctrl-reg = <0x3e4>;
			dline-reg = <0x3e8>;
			clocks = <&syscon_apmu CLK_EMAC0_BUS>,
				 <&syscon_apmu CLK_EMAC0_PTP>;
			clock-names = "emac-clk", "ptp-clk";
			resets = <&syscon_apmu RESET_EMAC0>;
			reset-names = "emac-reset";
			interrupts-extended = <&intc 131>;
			mac-address = [ 00 00 00 00 00 00 ];
			ptp-support;
			ptp-clk-rate = <10000000>;
			interconnects = <&dram_range1>;
			interconnect-names = "dma-mem";
			status = "disabled";
		};

		eth1: ethernet@cac81000 {
			compatible = "spacemit,k1-emac";
			reg = <0x0 0xCAC81000 0x0 0x420>;
			k1,apmu-base-reg = <0xD4282800>;
			ctrl-reg = <0x3ec>;
			dline-reg = <0x3f0>;
			clocks = <&syscon_apmu CLK_EMAC1_BUS>,
				 <&syscon_apmu CLK_EMAC1_PTP>;
			clock-names = "emac-clk", "ptp-clk";
			resets = <&syscon_apmu RESET_EMAC1>;
			reset-names = "emac-reset";
			interrupts-extended = <&intc 133>;
			mac-address = [ 00 00 00 00 00 00 ];
			ptp-support;
			ptp-clk-rate = <10000000>;
			interconnects = <&dram_range1>;
			interconnect-names = "dma-mem";
			status = "disabled";
		};
	};
};
